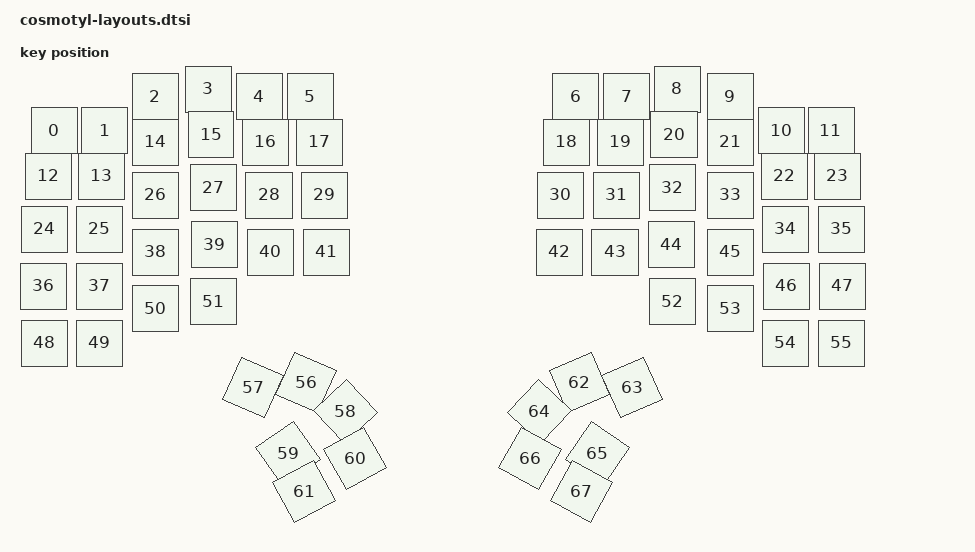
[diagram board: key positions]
#include <physical_layouts.dtsi>

/ {
    default_layout: physical_layout_0 {
        compatible = "zmk,physical-layout";
        display-name = "Default Layout";
        transform = <&default_transform>;

        keys
            = <&key_physical_attrs 100 100 22 83 0 0 0>
            , <&key_physical_attrs 100 100 123 83 0 0 0>
            , <&key_physical_attrs 100 100 224 15 0 0 0>
            , <&key_physical_attrs 100 100 330 0 0 0 0>
            , <&key_physical_attrs 100 100 432 15 0 0 0>
            , <&key_physical_attrs 100 100 534 15 0 0 0>
            , <&key_physical_attrs 100 100 1065 15 0 0 0>
            , <&key_physical_attrs 100 100 1167 15 0 0 0>
            , <&key_physical_attrs 100 100 1268 0 0 0 0>
            , <&key_physical_attrs 100 100 1374 15 0 0 0>
            , <&key_physical_attrs 100 100 1476 83 0 0 0>
            , <&key_physical_attrs 100 100 1576 83 0 0 0>
            , <&key_physical_attrs 100 100 10 174 0 0 0>
            , <&key_physical_attrs 100 100 117 174 0 0 0>
            , <&key_physical_attrs 100 100 224 106 0 0 0>
            , <&key_physical_attrs 100 100 336 91 0 0 0>
            , <&key_physical_attrs 100 100 444 106 0 0 0>
            , <&key_physical_attrs 100 100 552 106 0 0 0>
            , <&key_physical_attrs 100 100 1047 106 0 0 0>
            , <&key_physical_attrs 100 100 1155 106 0 0 0>
            , <&key_physical_attrs 100 100 1262 91 0 0 0>
            , <&key_physical_attrs 100 100 1374 106 0 0 0>
            , <&key_physical_attrs 100 100 1482 174 0 0 0>
            , <&key_physical_attrs 100 100 1588 174 0 0 0>
            , <&key_physical_attrs 100 100 3 280 0 0 0>
            , <&key_physical_attrs 100 100 113 280 0 0 0>
            , <&key_physical_attrs 100 100 224 212 0 0 0>
            , <&key_physical_attrs 100 100 340 197 0 0 0>
            , <&key_physical_attrs 100 100 452 212 0 0 0>
            , <&key_physical_attrs 100 100 563 212 0 0 0>
            , <&key_physical_attrs 100 100 1035 212 0 0 0>
            , <&key_physical_attrs 100 100 1147 212 0 0 0>
            , <&key_physical_attrs 100 100 1258 197 0 0 0>
            , <&key_physical_attrs 100 100 1374 212 0 0 0>
            , <&key_physical_attrs 100 100 1485 280 0 0 0>
            , <&key_physical_attrs 100 100 1596 280 0 0 0>
            , <&key_physical_attrs 100 100 0 394 0 0 0>
            , <&key_physical_attrs 100 100 112 394 0 0 0>
            , <&key_physical_attrs 100 100 224 326 0 0 0>
            , <&key_physical_attrs 100 100 342 311 0 0 0>
            , <&key_physical_attrs 100 100 454 326 0 0 0>
            , <&key_physical_attrs 100 100 567 326 0 0 0>
            , <&key_physical_attrs 100 100 1032 326 0 0 0>
            , <&key_physical_attrs 100 100 1144 326 0 0 0>
            , <&key_physical_attrs 100 100 1257 311 0 0 0>
            , <&key_physical_attrs 100 100 1374 326 0 0 0>
            , <&key_physical_attrs 100 100 1487 394 0 0 0>
            , <&key_physical_attrs 100 100 1598 394 0 0 0>
            , <&key_physical_attrs 100 100 3 508 0 0 0>
            , <&key_physical_attrs 100 100 113 508 0 0 0>
            , <&key_physical_attrs 100 100 224 439 0 0 0>
            , <&key_physical_attrs 100 100 340 425 0 0 0>
            , <&key_physical_attrs 100 100 1258 425 0 0 0>
            , <&key_physical_attrs 100 100 1374 439 0 0 0>
            , <&key_physical_attrs 100 100 1485 508 0 0 0>
            , <&key_physical_attrs 100 100 1596 508 0 0 0>
            , <&key_physical_attrs 100 100 526 587 11382 576 637>
            , <&key_physical_attrs 100 100 420 597 11382 470 647>
            , <&key_physical_attrs 100 100 605 645 4736 655 695>
            , <&key_physical_attrs 100 100 490 729 5531 540 779>
            , <&key_physical_attrs 100 100 624 739 6055 674 789>
            , <&key_physical_attrs 100 100 522 805 6148 572 855>
            , <&key_physical_attrs 100 100 1073 587 (-11382) 1123 637>
            , <&key_physical_attrs 100 100 1178 597 (-11382) 1228 647>
            , <&key_physical_attrs 100 100 993 645 (-4736) 1043 695>
            , <&key_physical_attrs 100 100 1109 729 (-5531) 1159 779>
            , <&key_physical_attrs 100 100 974 739 (-6055) 1024 789>
            , <&key_physical_attrs 100 100 1077 805 (-6148) 1127 855>
            ;
    };
};

